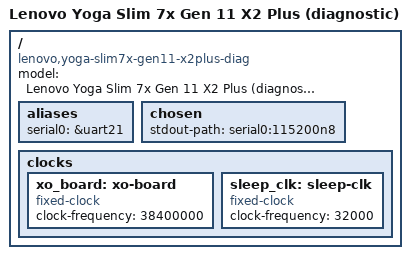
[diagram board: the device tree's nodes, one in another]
// SPDX-License-Identifier: BSD-3-Clause
/dts-v1/;

#include "kalambo.dtsi"

/ {
	model = "Lenovo Yoga Slim 7x Gen 11 X2 Plus (diagnostic)";
	compatible = "lenovo,yoga-slim7x-gen11-x2plus-diag", "qcom,kalambo";

	aliases {
		serial0 = &uart21;
	};

	chosen {
		stdout-path = "serial0:115200n8";
	};

	clocks {
		xo_board: xo-board {
			compatible = "fixed-clock";
			clock-frequency = <38400000>;
			#clock-cells = <0>;
		};

		sleep_clk: sleep-clk {
			compatible = "fixed-clock";
			clock-frequency = <32000>;
			#clock-cells = <0>;
		};
	};
};
